# S6E1C3xD register map
Vendor: Cypress; File version: 2.1
CPU: CM0PLUS r0p1, little endian, no MPU, no FPU, 2 interrupt priority bits
Registers are 32-bit, read-write, reset 0x0 unless marked. A register's access mark holds for its fields unless they carry their own. Offsets are from the block's base; [hi:lo] are bit positions; {n}, {i} and the like mark numbered series.

## GPIO — I/O Port Registers
Base 0x40033000
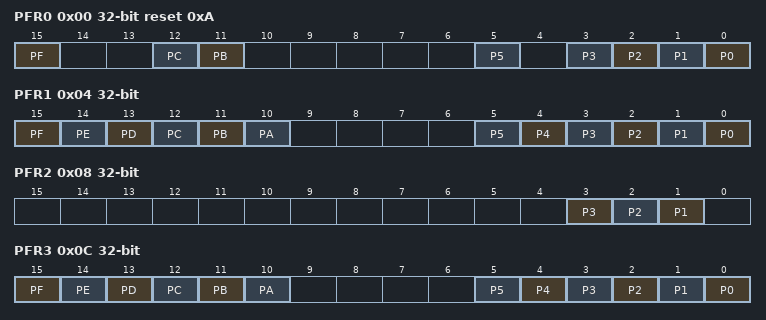
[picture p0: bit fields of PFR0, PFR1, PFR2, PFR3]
0x00 PFR0 reset 0xA — Port Function Setting Register 0 [BHW]
  [15] PF — Bit15 of PFR0
  [12] PC — Bit12 of PFR0
  [11] PB — Bit11 of PFR0
  [5] P5 — Bit5 of PFR0
  [n] P{n} (n=0..3) — Bit{n} of PFR0
0x04 PFR1 — Port Function Setting Register 1 [BHW]
  [15] PF — Bit15 of PFR1
  [14] PE — Bit14 of PFR1
  [13] PD — Bit13 of PFR1
  [12] PC — Bit12 of PFR1
  [11] PB — Bit11 of PFR1
  [10] PA — Bit10 of PFR1
  [n] P{n} (n=0..5) — Bit{n} of PFR1
0x08 PFR2 — Port Function Setting Register 2 [BHW]
  [3] P3 — Bit3 of PFR2
  [2] P2 — Bit2 of PFR2
  [1] P1 — Bit1 of PFR2
0x0C PFR3 — Port Function Setting Register 3 [BHW]
  [15] PF — Bit15 of PFR3
  [14] PE — Bit14 of PFR3
  [13] PD — Bit13 of PFR3
  [12] PC — Bit12 of PFR3
  [11] PB — Bit11 of PFR3
  [10] PA — Bit10 of PFR3
  [n] P{n} (n=0..5) — Bit{n} of PFR3
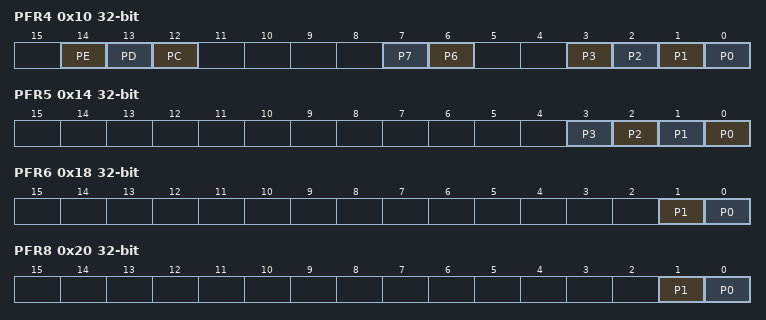
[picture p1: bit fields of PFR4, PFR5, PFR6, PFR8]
0x10 PFR4 — Port Function Setting Register 4 [BHW]
  [14] PE — Bit14 of PFR4
  [13] PD — Bit13 of PFR4
  [12] PC — Bit12 of PFR4
  [7] P7 — Bit7 of PFR4
  [6] P6 — Bit6 of PFR4
  [n] P{n} (n=0..3) — Bit{n} of PFR4
0x14 PFR5 — Port Function Setting Register 5 [BHW]
  [n] P{n} (n=0..3) — Bit{n} of PFR5
0x18 PFR6 — Port Function Setting Register 6 [BHW]
  [1] P1 — Bit1 of PFR6
  [0] P0 — Bit0 of PFR6
0x1C PFR7 reset not defined — Port Function Setting Register 7 [BHW]
0x20 PFR8 — Port Function Setting Register 8 [BHW]
  [1] P1 — Bit1 of PFR8
  [0] P0 — Bit0 of PFR8
0x24 PFR9 reset not defined — Port Function Setting Register 9 [BHW]
0x28 PFRA reset not defined — Port Function Setting Register A [BHW]
0x2C PFRB reset not defined — Port Function Setting Register B [BHW]
0x30 PFRC reset not defined — Port Function Setting Register C [BHW]
0x34 PFRD reset not defined — Port Function Setting Register D [BHW]
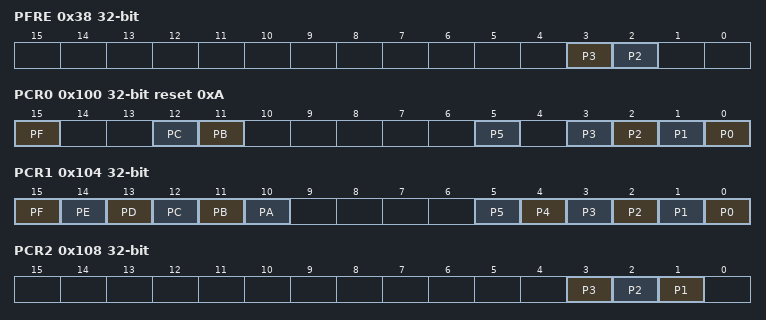
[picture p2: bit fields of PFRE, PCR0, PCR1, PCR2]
0x38 PFRE — Port Function Setting Register E [BHW]
  [3] P3 — Bit3 of PFRE
  [2] P2 — Bit2 of PFRE
0x3C PFRF reset not defined — Port Function Setting Register F [BHW]
0x100 PCR0 reset 0xA — Pull-up Setting Register 0 [BHW]
  [15] PF — Bit15 of PCR0
  [12] PC — Bit12 of PCR0
  [11] PB — Bit11 of PCR0
  [5] P5 — Bit5 of PCR0
  [n] P{n} (n=0..3) — Bit{n} of PCR0
0x104 PCR1 — Pull-up Setting Register 1 [BHW]
  [15] PF — Bit15 of PCR1
  [14] PE — Bit14 of PCR1
  [13] PD — Bit13 of PCR1
  [12] PC — Bit12 of PCR1
  [11] PB — Bit11 of PCR1
  [10] PA — Bit10 of PCR1
  [n] P{n} (n=0..5) — Bit{n} of PCR1
0x108 PCR2 — Pull-up Setting Register 2 [BHW]
  [3] P3 — Bit3 of PCR2
  [2] P2 — Bit2 of PCR2
  [1] P1 — Bit1 of PCR2
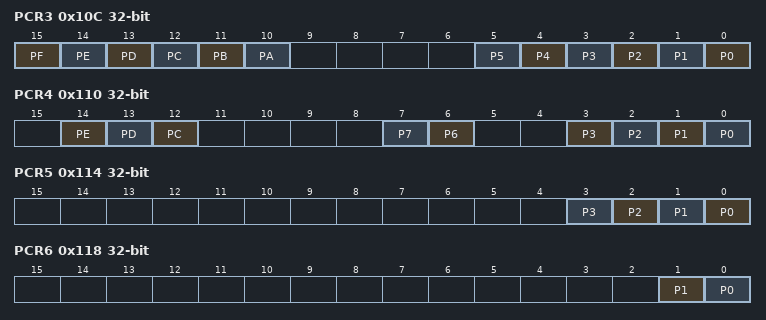
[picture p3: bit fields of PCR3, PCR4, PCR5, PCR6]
0x10C PCR3 — Pull-up Setting Register 3 [BHW]
  [15] PF — Bit15 of PCR3
  [14] PE — Bit14 of PCR3
  [13] PD — Bit13 of PCR3
  [12] PC — Bit12 of PCR3
  [11] PB — Bit11 of PCR3
  [10] PA — Bit10 of PCR3
  [n] P{n} (n=0..5) — Bit{n} of PCR3
0x110 PCR4 — Pull-up Setting Register 4 [BHW]
  [14] PE — Bit14 of PCR4
  [13] PD — Bit13 of PCR4
  [12] PC — Bit12 of PCR4
  [7] P7 — Bit7 of PCR4
  [6] P6 — Bit6 of PCR4
  [n] P{n} (n=0..3) — Bit{n} of PCR4
0x114 PCR5 — Pull-up Setting Register 5 [BHW]
  [n] P{n} (n=0..3) — Bit{n} of PCR5
0x118 PCR6 — Pull-up Setting Register 6 [BHW]
  [1] P1 — Bit1 of PCR6
  [0] P0 — Bit0 of PCR6
0x11C PCR7 reset not defined — Pull-up Setting Register 7 [BHW]
0x124 PCR9 reset not defined — Pull-up Setting Register 9 [BHW]
0x128 PCRA reset not defined — Pull-up Setting Register A [BHW]
0x12C PCRB reset not defined — Pull-up Setting Register B [BHW]
0x130 PCRC reset not defined — Pull-up Setting Register C [BHW]
0x134 PCRD reset not defined — Pull-up Setting Register D [BHW]
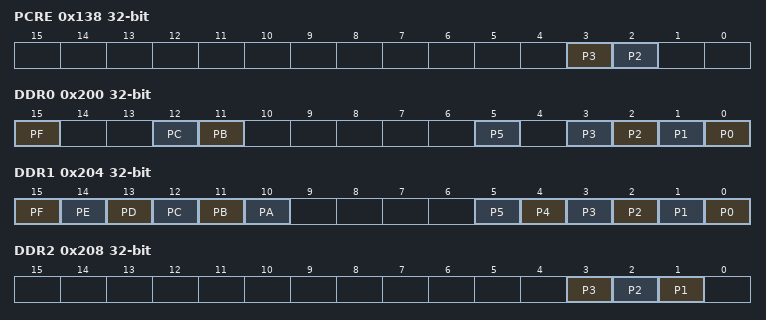
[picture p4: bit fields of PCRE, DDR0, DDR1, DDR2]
0x138 PCRE — Pull-up Setting Register E [BHW]
  [3] P3 — Bit3 of PCRE
  [2] P2 — Bit2 of PCRE
0x13C PCRF reset not defined — Pull-up Setting Register F [BHW]
0x200 DDR0 — Port input/output Direction Setting Register 0 [BHW]
  [15] PF — Bit15 of DDR0
  [12] PC — Bit12 of DDR0
  [11] PB — Bit11 of DDR0
  [5] P5 — Bit5 of DDR0
  [n] P{n} (n=0..3) — Bit{n} of DDR0
0x204 DDR1 — Port input/output Direction Setting Register 1 [BHW]
  [15] PF — Bit15 of DDR1
  [14] PE — Bit14 of DDR1
  [13] PD — Bit13 of DDR1
  [12] PC — Bit12 of DDR1
  [11] PB — Bit11 of DDR1
  [10] PA — Bit10 of DDR1
  [n] P{n} (n=0..5) — Bit{n} of DDR1
0x208 DDR2 — Port input/output Direction Setting Register 2 [BHW]
  [3] P3 — Bit3 of DDR2
  [2] P2 — Bit2 of DDR2
  [1] P1 — Bit1 of DDR2
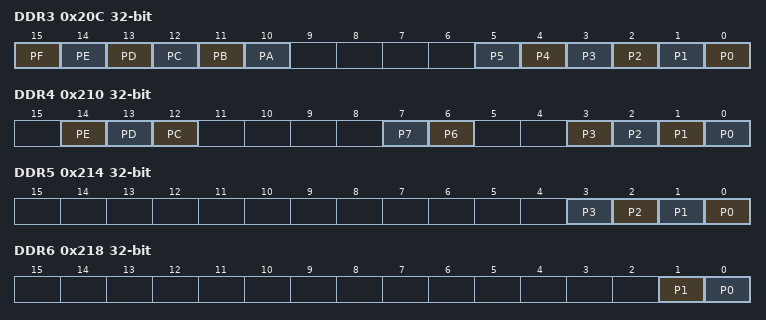
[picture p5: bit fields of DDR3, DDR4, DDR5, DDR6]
0x20C DDR3 — Port input/output Direction Setting Register 3 [BHW]
  [15] PF — Bit15 of DDR3
  [14] PE — Bit14 of DDR3
  [13] PD — Bit13 of DDR3
  [12] PC — Bit12 of DDR3
  [11] PB — Bit11 of DDR3
  [10] PA — Bit10 of DDR3
  [n] P{n} (n=0..5) — Bit{n} of DDR3
0x210 DDR4 — Port input/output Direction Setting Register 4 [BHW]
  [14] PE — Bit14 of DDR4
  [13] PD — Bit13 of DDR4
  [12] PC — Bit12 of DDR4
  [7] P7 — Bit7 of DDR4
  [6] P6 — Bit6 of DDR4
  [n] P{n} (n=0..3) — Bit{n} of DDR4
0x214 DDR5 — Port input/output Direction Setting Register 5 [BHW]
  [n] P{n} (n=0..3) — Bit{n} of DDR5
0x218 DDR6 — Port input/output Direction Setting Register 6 [BHW]
  [1] P1 — Bit1 of DDR6
  [0] P0 — Bit0 of DDR6
0x21C DDR7 reset not defined — Port input/output Direction Setting Register 7 [BHW]
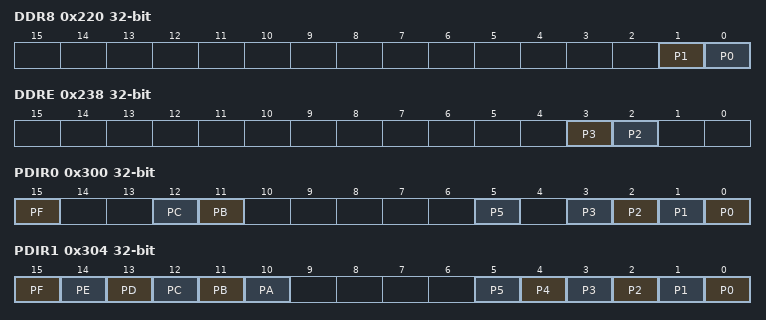
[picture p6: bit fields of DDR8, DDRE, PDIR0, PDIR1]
0x220 DDR8 — Port input/output Direction Setting Register 8 [BHW]
  [1] P1 — Bit1 of DDR8
  [0] P0 — Bit0 of DDR8
0x224 DDR9 reset not defined — Port input/output Direction Setting Register 9 [BHW]
0x228 DDRA reset not defined — Port input/output Direction Setting Register A [BHW]
0x22C DDRB reset not defined — Port input/output Direction Setting Register B [BHW]
0x230 DDRC reset not defined — Port input/output Direction Setting Register C [BHW]
0x234 DDRD reset not defined — Port input/output Direction Setting Register D [BHW]
0x238 DDRE — Port input/output Direction Setting Register E [BHW]
  [3] P3 — Bit3 of DDRE
  [2] P2 — Bit2 of DDRE
0x23C DDRF reset not defined — Port input/output Direction Setting Register F [BHW]
0x300 PDIR0 ro — Port Input Data Register 0 [BHW]
  [15] PF rw — Bit15 of PDIR0
  [12] PC rw — Bit12 of PDIR0
  [11] PB rw — Bit11 of PDIR0
  [5] P5 rw — Bit5 of PDIR0
  [n] P{n} rw (n=0..3) — Bit{n} of PDIR0
0x304 PDIR1 ro — Port Input Data Register 1 [BHW]
  [15] PF rw — Bit15 of PDIR1
  [14] PE rw — Bit14 of PDIR1
  [13] PD rw — Bit13 of PDIR1
  [12] PC rw — Bit12 of PDIR1
  [11] PB rw — Bit11 of PDIR1
  [10] PA rw — Bit10 of PDIR1
  [n] P{n} rw (n=0..5) — Bit{n} of PDIR1
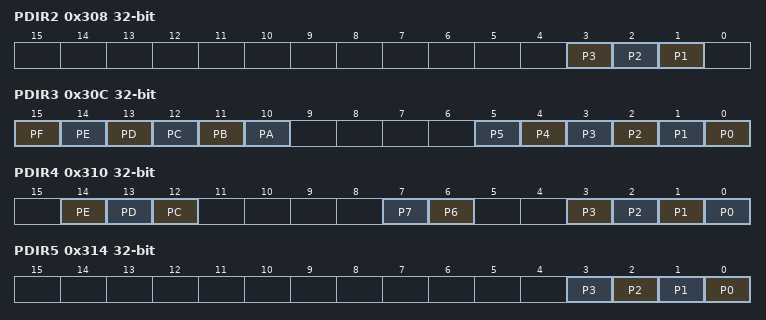
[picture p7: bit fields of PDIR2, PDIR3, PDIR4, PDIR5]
0x308 PDIR2 ro — Port Input Data Register 2 [BHW]
  [3] P3 rw — Bit3 of PDIR2
  [2] P2 rw — Bit2 of PDIR2
  [1] P1 rw — Bit1 of PDIR2
0x30C PDIR3 ro — Port Input Data Register 3 [BHW]
  [15] PF rw — Bit15 of PDIR3
  [14] PE rw — Bit14 of PDIR3
  [13] PD rw — Bit13 of PDIR3
  [12] PC rw — Bit12 of PDIR3
  [11] PB rw — Bit11 of PDIR3
  [10] PA rw — Bit10 of PDIR3
  [n] P{n} rw (n=0..5) — Bit{n} of PDIR3
0x310 PDIR4 ro — Port Input Data Register 4 [BHW]
  [14] PE rw — Bit14 of PDIR4
  [13] PD rw — Bit13 of PDIR4
  [12] PC rw — Bit12 of PDIR4
  [7] P7 rw — Bit7 of PDIR4
  [6] P6 rw — Bit6 of PDIR4
  [n] P{n} rw (n=0..3) — Bit{n} of PDIR4
0x314 PDIR5 ro — Port Input Data Register 5 [BHW]
  [n] P{n} rw (n=0..3) — Bit{n} of PDIR5
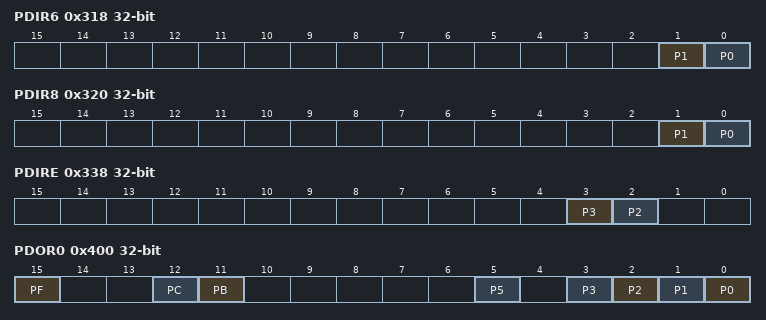
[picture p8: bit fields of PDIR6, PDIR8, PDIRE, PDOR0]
0x318 PDIR6 ro — Port Input Data Register 6 [BHW]
  [1] P1 rw — Bit1 of PDIR6
  [0] P0 rw — Bit0 of PDIR6
0x31C PDIR7 ro reset not defined — Port Input Data Register 7 [BHW]
0x320 PDIR8 ro — Port Input Data Register 8 [BHW]
  [1] P1 rw — Bit1 of PDIR8
  [0] P0 rw — Bit0 of PDIR8
0x324 PDIR9 ro reset not defined — Port Input Data Register 9 [BHW]
0x328 PDIRA ro reset not defined — Port Input Data Register A [BHW]
0x32C PDIRB ro reset not defined — Port Input Data Register B [BHW]
0x330 PDIRC ro reset not defined — Port Input Data Register C [BHW]
0x334 PDIRD ro reset not defined — Port Input Data Register D [BHW]
0x338 PDIRE ro — Port Input Data Register E [BHW]
  [3] P3 rw — Bit3 of PDIRE
  [2] P2 rw — Bit2 of PDIRE
0x33C PDIRF ro reset not defined — Port Input Data Register F [BHW]
0x400 PDOR0 — Port Output Data Register 0 [BHW]
  [15] PF — Bit15 of PDOR0
  [12] PC — Bit12 of PDOR0
  [11] PB — Bit11 of PDOR0
  [5] P5 — Bit5 of PDOR0
  [n] P{n} (n=0..3) — Bit{n} of PDOR0
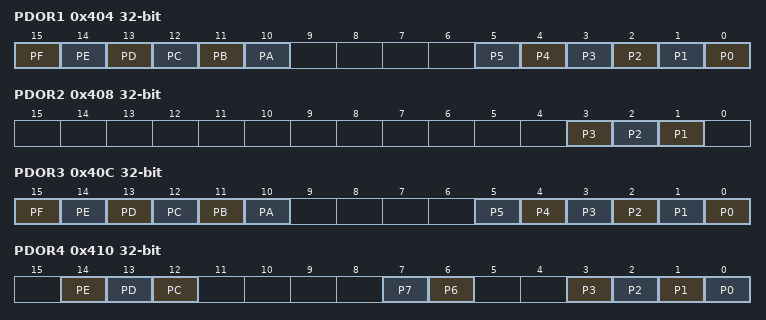
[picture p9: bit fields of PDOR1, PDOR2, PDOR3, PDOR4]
0x404 PDOR1 — Port Output Data Register 1 [BHW]
  [15] PF — Bit15 of PDOR1
  [14] PE — Bit14 of PDOR1
  [13] PD — Bit13 of PDOR1
  [12] PC — Bit12 of PDOR1
  [11] PB — Bit11 of PDOR1
  [10] PA — Bit10 of PDOR1
  [n] P{n} (n=0..5) — Bit{n} of PDOR1
0x408 PDOR2 — Port Output Data Register 2 [BHW]
  [3] P3 — Bit3 of PDOR2
  [2] P2 — Bit2 of PDOR2
  [1] P1 — Bit1 of PDOR2
0x40C PDOR3 — Port Output Data Register 3 [BHW]
  [15] PF — Bit15 of PDOR3
  [14] PE — Bit14 of PDOR3
  [13] PD — Bit13 of PDOR3
  [12] PC — Bit12 of PDOR3
  [11] PB — Bit11 of PDOR3
  [10] PA — Bit10 of PDOR3
  [n] P{n} (n=0..5) — Bit{n} of PDOR3
0x410 PDOR4 — Port Output Data Register 4 [BHW]
  [14] PE — Bit14 of PDOR4
  [13] PD — Bit13 of PDOR4
  [12] PC — Bit12 of PDOR4
  [7] P7 — Bit7 of PDOR4
  [6] P6 — Bit6 of PDOR4
  [n] P{n} (n=0..3) — Bit{n} of PDOR4
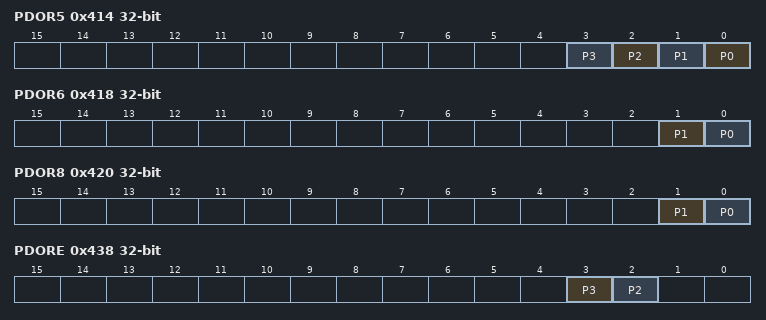
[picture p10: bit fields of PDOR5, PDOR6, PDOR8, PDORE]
0x414 PDOR5 — Port Output Data Register 5 [BHW]
  [n] P{n} (n=0..3) — Bit{n} of PDOR5
0x418 PDOR6 — Port Output Data Register 6 [BHW]
  [1] P1 — Bit1 of PDOR6
  [0] P0 — Bit0 of PDOR6
0x41C PDOR7 reset not defined — Port Output Data Register 7 [BHW]
0x420 PDOR8 — Port Output Data Register 8 [BHW]
  [1] P1 — Bit1 of PDOR8
  [0] P0 — Bit0 of PDOR8
0x424 PDOR9 reset not defined — Port Output Data Register 9 [BHW]
0x428 PDORA reset not defined — Port Output Data Register A [BHW]
0x42C PDORB reset not defined — Port Output Data Register B [BHW]
0x430 PDORC reset not defined — Port Output Data Register C [BHW]
0x434 PDORD reset not defined — Port Output Data Register D [BHW]
0x438 PDORE — Port Output Data Register E [BHW]
  [3] P3 — Bit3 of PDORE
  [2] P2 — Bit2 of PDORE
0x43C PDORF reset not defined — Port Output Data Register F [BHW]
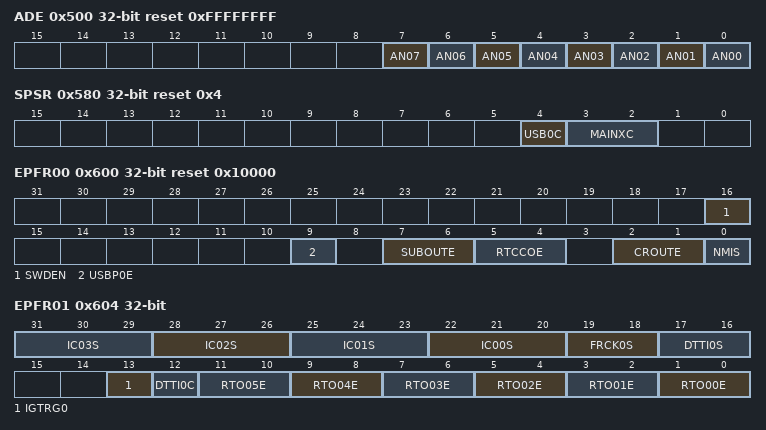
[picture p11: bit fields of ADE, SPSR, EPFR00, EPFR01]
0x500 ADE reset 0xFFFFFFFF — Analog Input Setting Register [BHW]
  [7] AN07 — Analog Input Ch.7 Setting Register
  [6] AN06 — Analog Input Ch.6 Setting Register
  [5] AN05 — Analog Input Ch.5 Setting Register
  [4] AN04 — Analog Input Ch.4 Setting Register
  [3] AN03 — Analog Input Ch.3 Setting Register
  [2] AN02 — Analog Input Ch.2 Setting Register
  [1] AN01 — Analog Input Ch.1 Setting Register
  [0] AN00 — Analog Input Ch.0 Setting Register
0x580 SPSR reset 0x4 — Special Port Setting Register [BHW]
  [4] USB0C — USB (ch.0) Pin Setting Register
  [3:2] MAINXC — Main Clock (Oscillation) Pin Setting Register
0x600 EPFR00 reset 0x10000 — Extended Pin Function Setting Register 00 [BHW]
  [16] SWDEN — Serial Wire Debug Function Select bit
  [9] USBP0E — USB ch.0 Function Select bit 1
  [7:6] SUBOUTE — Sub clock divide output function select bit
  [5:4] RTCCOE — RTC clock output select bit
  [2:1] CROUTE — Internal high-speed CR Oscillation Output Function Select bit
  [0] NMIS — NMIX Function Select bit
0x604 EPFR01 — Extended Pin Function Setting Register 01 [BHW]
  [3n+22:3n+20] IC{n:02}S (n=0..3) — IC{n:02} Input Select bits
  [19:18] FRCK0S — FRCK0 Input Select bits
  [17:16] DTTI0S — DTTIX0 Input Select bits
  [13] IGTRG0 — IGTRG0 Input Select bit
  [12] DTTI0C — DTTIX0 Function Select bit
  [2n+1:2n] RTO{n:02}E (n=0..5) — RTO{n:02} Output Select bits
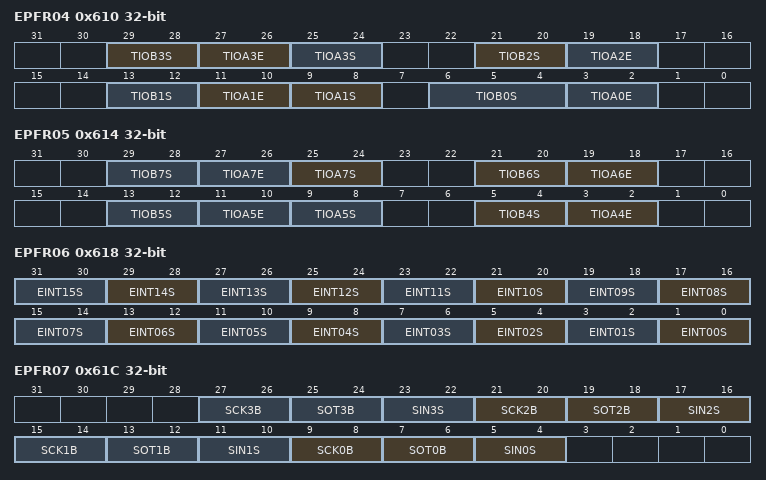
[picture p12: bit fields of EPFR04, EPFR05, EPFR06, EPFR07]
0x610 EPFR04 — Extended Pin Function Setting Register 04 [BHW]
  [29:28] TIOB3S — TIOB3 Input Select bits
  [8n+3:8n+2] TIOA{n}E (n=0..3) — TIOA{n} Output Select bits
  [25:24] TIOA3S — TIOA3 Input Select bits
  [21:20] TIOB2S — TIOB2 Input Select bits
  [13:12] TIOB1S — TIOB1 Input Select bits
  [9:8] TIOA1S — TIOA1 Input Select bits
  [6:4] TIOB0S — TIOB0 Input Select bits
0x614 EPFR05 — Extended Pin Function Setting Register 05 [BHW]
  [8n-27:8n-28] TIOB{n}S (n=4..7) — TIOB{n} Input Select bits
  [8n-29:8n-30] TIOA{n}E (n=4..7) — TIOA{n} Output Select bits
  [25:24] TIOA7S — TIOA7 Input Select bits
  [9:8] TIOA5S — TIOA5 Input Select bits
0x618 EPFR06 — Extended Pin Function Setting Register 06 [BHW]
  [2n+1:2n] EINT{n:02}S (n=0..15) — External Interrupt {n:02} Input Select bits
0x61C EPFR07 — Extended Pin Function Setting Register 07 [BHW]
  [6n+9:6n+8] SCK{n}B (n=0..3) — SCK{n} Input/Output Select bits
  [6n+7:6n+6] SOT{n}B (n=0..3) — SOT{n} Input/Output Select bits
  [6n+5:6n+4] SIN{n}S (n=0..3) — SIN{n} Input Select bits
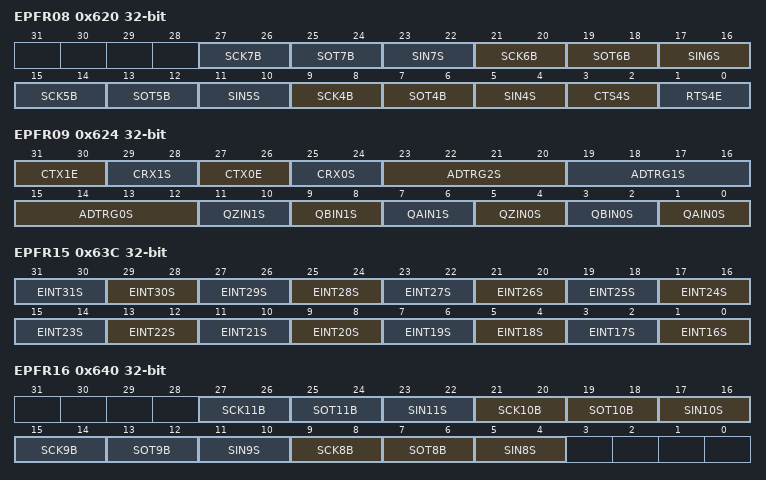
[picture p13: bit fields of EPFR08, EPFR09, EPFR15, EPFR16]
0x620 EPFR08 — Extended Pin Function Setting Register 08 [BHW]
  [6n-15:6n-16] SCK{n}B (n=4..7) — SCK{n} Input/Output Select bits
  [6n-17:6n-18] SOT{n}B (n=4..7) — SOT{n} Input/Output Select bits
  [6n-19:6n-20] SIN{n}S (n=4..7) — SIN{n} Input Select bits
  [3:2] CTS4S — CTS4 Input Select bits
  [1:0] RTS4E — RTS4 Output Select bits
0x624 EPFR09 — Extended Pin Function Setting Register 09 [BHW]
  [31:30] CTX1E — CTX1E Output Select bits
  [29:28] CRX1S — CRX1S Input Select bits
  [27:26] CTX0E — CTX0E Output Select bits
  [25:24] CRX0S — CRX0S Input Select bits
  [23:20] ADTRG2S — ADTRG2 Input Select bits
  [19:16] ADTRG1S — ADTRG1 Input Select bits
  [15:12] ADTRG0S — ADTRG0 Input Select bits
  [11:10] QZIN1S — QZIN1S Input Select bits
  [9:8] QBIN1S — QBIN1S Input Select bits
  [7:6] QAIN1S — QAIN1S Input Select bits
  [5:4] QZIN0S — QZIN0S Input Select bits
  [3:2] QBIN0S — QBIN0S Input Select bits
  [1:0] QAIN0S — QAIN0S Input Select bits
0x63C EPFR15 — Extended Pin Function Setting Register 15 [BHW]
  [2n-31:2n-32] EINT{n}S (n=16..31) — External Interrupt {n} Input Select bits
0x640 EPFR16 — Extended Pin Function Setting Register 16 [BHW]
  [6n-39:6n-40] SCK{n}B (n=8..11) — SCK{n} Input/Output Select bits
  [6n-41:6n-42] SOT{n}B (n=8..11) — SOT{n} Input/Output Select bits
  [6n-43:6n-44] SIN{n}S (n=8..11) — SIN{n} Input Select bits
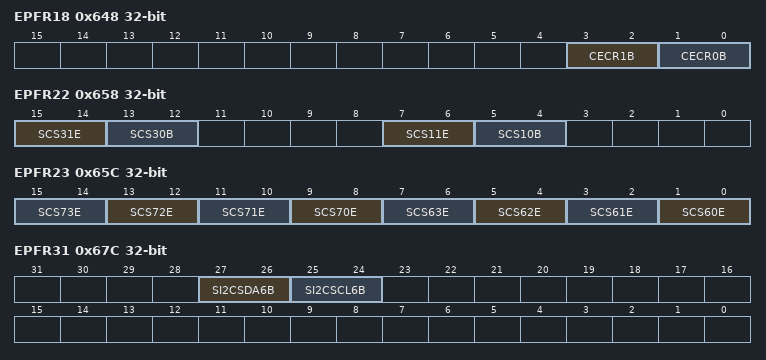
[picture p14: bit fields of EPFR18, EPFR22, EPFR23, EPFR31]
0x648 EPFR18 — Extended Pin Function Setting Register 18 [BHW]
  [3:2] CECR1B — CEC1 input/output selection bits
  [1:0] CECR0B — CEC0 input/output selection bits
0x658 EPFR22 — Extended Pin Function Setting Register 22 [BHW]
  [15:14] SCS31E — SCS31 Output Select bits
  [13:12] SCS30B — SCS30 Input/Output Select bits
  [7:6] SCS11E — SCS11 Output Select bits
  [5:4] SCS10B — SCS10 Input/Output Select bits
0x65C EPFR23 — Extended Pin Function Setting Register 23 [BHW]
  [2n-131:2n-132] SCS{n}E (n=70..73) — SCS{n} Output Select bits
  [2n-119:2n-120] SCS{n}E (n=60..63) — SCS{n} Output Select bits
0x67C EPFR31 — Extended Pin Function Setting Register 31 [BHW]
  [27:26] SI2CSDA6B — I2C Slave ch.6 SDA pin select bits
  [25:24] SI2CSCL6B — I2C Slave ch.6 SCL pin select bits
0x684 EPFR33 — Extended Pin Function Setting Register 33 [BHW]
  [27:26] CLK1E — CLK1 Output Select bits
  [25:24] VCC1E — VCC1 Output Select bits
  [23:22] VPEN1E — VPEN1 Output Select bits
  [21:20] RST1E — PST1 Output Select bits
  [19:18] DATA1B — DATA1 Bus Select bits
  [17:16] CIN1S — CIN1 Input Select bits
  [11:10] CLK0E — CLK0 Output Select bits
  [9:8] VCC0E — VCC0 Output Select bits
  [7:6] VPEN0E — VPEN0 Output Select bits
  [5:4] RST0E — RST0 Output Select bits
  [3:2] DATA0B — DATA0 Bus Select bits
  [1:0] CIN0S — CIN0 Input Select bits
0x688 EPFR34 — Extended Pin Function Setting Register 34 [BHW]
  [7:6] CTS1S — CTS1 Input Select bits
  [5:4] RTS1E — RTS1 Output Select bits
0x694 EPFR37 — Extended Pin Function Setting Register 37 [BHW]
  [27:26] SDO5E — MFSI2S I2SSDO5 Output Select bits
  [25:24] SDI5S — MFSI2S I2SDI5 Input Select bits
  [23:22] WS5B — I2SWS5 Input/Output Select bits
  [21:20] SCK5B — I2SCK5 Input/Output Select bits
  [19:18] MCK5E — I2SMCLK5 Output Select bits
  [17:16] MCK5S — I2SMCLK5 Input Select bits
  [11:10] SDO4E — MFSI2S I2SSDO4 Output Select bits
  [9:8] SDI4S — MFSI2S I2SDI4 Input Select bits
  [7:6] WS4B — I2SWS4 Input/Output Select bits
  [5:4] SCK4B — I2SCK4 Input/Output Select bits
  [3:2] MCK4E — I2SMCLK4 Output Select bits
  [1:0] MCK4S — I2SMCLK4 Input Select bits
0x698 EPFR38 — Extended Pin Function Setting Register 38 [BHW]
  [11:10] SDO6E — MFSI2S I2SDO6 Output Select bits
  [9:8] SDI6S — MFSI2S I2SDI6 Input Select bits
  [7:6] WS6B — I2SWS6 Input/Output Select bits
  [5:4] SCK6B — I2SCK6 Input/Output Select bits
  [3:2] MCK6E — I2SMCLK6 Output Select bits
  [1:0] MCK6S — I2SMCLK6 Input Select bits
0x700 PZR0 — Port Pseudo Open Drain Setting Register 0 [BHW]
  [15] PF — Bit15 of PZR0
  [12] PC — Bit12 of PZR0
  [11] PB — Bit11 of PZR0
  [5] P5 — Bit5 of PZR0
  [n] P{n} (n=0..3) — Bit{n} of PZR0
0x704 PZR1 — Port Pseudo Open Drain Setting Register 1 [BHW]
  [15] PF — Bit15 of PZR1
  [14] PE — Bit14 of PZR1
  [13] PD — Bit13 of PZR1
  [12] PC — Bit12 of PZR1
  [11] PB — Bit11 of PZR1
  [10] PA — Bit10 of PZR1
  [n] P{n} (n=0..5) — Bit{n} of PZR1
0x708 PZR2 — Port Pseudo Open Drain Setting Register 2 [BHW]
  [3] P3 — Bit3 of PZR2
  [2] P2 — Bit2 of PZR2
  [1] P1 — Bit1 of PZR2
0x70C PZR3 — Port Pseudo Open Drain Setting Register 3 [BHW]
  [15] PF — Bit15 of PZR3
  [14] PE — Bit14 of PZR3
  [13] PD — Bit13 of PZR3
  [12] PC — Bit12 of PZR3
  [11] PB — Bit11 of PZR3
  [10] PA — Bit10 of PZR3
  [n] P{n} (n=0..5) — Bit{n} of PZR3
0x710 PZR4 — Port Pseudo Open Drain Setting Register 4 [BHW]
  [14] PE — Bit14 of PZR4
  [13] PD — Bit13 of PZR4
  [12] PC — Bit12 of PZR4
  [7] P7 — Bit7 of PZR4
  [6] P6 — Bit6 of PZR4
  [n] P{n} (n=0..3) — Bit{n} of PZR4
0x714 PZR5 — Port Pseudo Open Drain Setting Register 5 [BHW]
  [n] P{n} (n=0..3) — Bit{n} of PZR5
0x718 PZR6 — Port Pseudo Open Drain Setting Register 6 [BHW]
  [1] P1 — Bit1 of PZR6
  [0] P0 — Bit0 of PZR6
0x71C PZR7 reset not defined — Port Pseudo Open Drain Setting Register 7 [BHW]
0x720 PZR8 — Port Pseudo Open Drain Setting Register 8 [BHW]
  [1] P1 — Bit1 of PZR8
  [0] P0 — Bit0 of PZR8
0x724 PZR9 reset not defined — Port Pseudo Open Drain Setting Register 9 [BHW]
0x728 PZRA reset not defined — Port Pseudo Open Drain Setting Register A [BHW]
0x72C PZRB reset not defined — Port Pseudo Open Drain Setting Register B [BHW]
0x730 PZRC reset not defined — Port Pseudo Open Drain Setting Register C [BHW]
0x734 PZRD reset not defined — Port Pseudo Open Drain Setting Register D [BHW]
0x738 PZRE — Port Pseudo Open Drain Setting Register E [BHW]
  [3] P3 — Bit3 of PZRE
  [2] P2 — Bit2 of PZRE
0x73C PZRF reset not defined — Port Pseudo Open Drain Setting Register F [BHW]
0x740 LVDIE — LVDI Input Setting Register [BHW]
  [0] LVDIE — LVDI Input select bit
0x900 FPOER0 wo — Fast GPIO Output Enable Register 0 [BHW]
  [15] PF rw — Bit15 of FPOER0
  [12] PC rw — Bit12 of FPOER0
  [11] PB rw — Bit11 of FPOER0
  [5] P5 rw — Bit5 of FPOER0
  [n] P{n} rw (n=0..3) — Bit{n} of FPOER0
0x904 FPOER1 wo — Fast GPIO Output Enable Register 1 [BHW]
  [15] PF rw — Bit15 of FPOER1
  [14] PE rw — Bit14 of FPOER1
  [13] PD rw — Bit13 of FPOER1
  [12] PC rw — Bit12 of FPOER1
  [11] PB rw — Bit11 of FPOER1
  [10] PA rw — Bit10 of FPOER1
  [n] P{n} rw (n=0..5) — Bit{n} of FPOER1
0x908 FPOER2 wo — Fast GPIO Output Enable Register 2 [BHW]
  [3] P3 rw — Bit3 of FPOER2
  [2] P2 rw — Bit2 of FPOER2
  [1] P1 rw — Bit1 of FPOER2
0x90C FPOER3 wo — Fast GPIO Output Enable Register 3 [BHW]
  [15] PF rw — Bit15 of FPOER3
  [14] PE rw — Bit14 of FPOER3
  [13] PD rw — Bit13 of FPOER3
  [12] PC rw — Bit12 of FPOER3
  [11] PB rw — Bit11 of FPOER3
  [10] PA rw — Bit10 of FPOER3
  [n] P{n} rw (n=0..5) — Bit{n} of FPOER3
0x910 FPOER4 wo — Fast GPIO Output Enable Register 4 [BHW]
  [14] PE rw — Bit14 of FPOER4
  [13] PD rw — Bit13 of FPOER4
  [12] PC rw — Bit12 of FPOER4
  [7] P7 rw — Bit7 of FPOER4
  [6] P6 rw — Bit6 of FPOER4
  [n] P{n} rw (n=0..3) — Bit{n} of FPOER4
0x914 FPOER5 wo — Fast GPIO Output Enable Register 5 [BHW]
  [n] P{n} rw (n=0..3) — Bit{n} of FPOER5
0x918 FPOER6 wo — Fast GPIO Output Enable Register 6 [BHW]
  [1] P1 rw — Bit1 of FPOER6
  [0] P0 rw — Bit0 of FPOER6
0x91C FPOER7 wo reset not defined — Fast GPIO Output Enable Register 7 [BHW]
0x920 FPOER8 wo — Fast GPIO Output Enable Register 8 [BHW]
  [1] P1 rw — Bit1 of FPOER8
  [0] P0 rw — Bit0 of FPOER8
0x924 FPOER9 wo reset not defined — Fast GPIO Output Enable Register 9 [BHW]
0x928 FPOERA wo reset not defined — Fast GPIO Output Enable Register A [BHW]
0x92C FPOERB wo reset not defined — Fast GPIO Output Enable Register B [BHW]
0x930 FPOERC wo reset not defined — Fast GPIO Output Enable Register C [BHW]
0x934 FPOERD wo reset not defined — Fast GPIO Output Enable Register D [BHW]
0x938 FPOERE wo — Fast GPIO Output Enable Register E [BHW]
  [3] P3 rw — Bit3 of FPOERE
  [2] P2 rw — Bit2 of FPOERE
0x93C FPOERF wo reset not defined — Fast GPIO Output Enable Register F [BHW]
